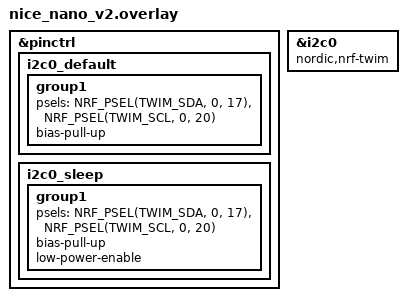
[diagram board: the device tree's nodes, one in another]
/*
 * Copyright (c) 2025 The ZMK Contributors
 *
 * SPDX-License-Identifier: MIT
 */

/* Override I2C configuration for trackpad with internal pull-ups
 * Upstream pinctrl does NOT enable bias-pull-up, so we need to override it.
 */

#include <dt-bindings/pinctrl/nrf-pinctrl.h>

&pinctrl {
    i2c0_default: i2c0_default {
        group1 {
            psels = <NRF_PSEL(TWIM_SDA, 0, 17)>,
                    <NRF_PSEL(TWIM_SCL, 0, 20)>;
            bias-pull-up;  // Enable internal pull-ups (missing in upstream!)
        };
    };

    i2c0_sleep: i2c0_sleep {
        group1 {
            psels = <NRF_PSEL(TWIM_SDA, 0, 17)>,
                    <NRF_PSEL(TWIM_SCL, 0, 20)>;
            bias-pull-up;  // Keep pull-ups during sleep
            low-power-enable;
        };
    };
};

&i2c0 {
    compatible = "nordic,nrf-twim";
    status = "okay";
};
